# ESP32-S2-ULP register map
Vendor: ESPRESSIF SYSTEMS (SHANGHAI) CO., LTD.; Series: RISC-V ULP; File version: 1
32-bit RISC-V MCU
CPU: RV32IMC r0p0, little endian, no MPU, no FPU, 4 interrupt priority bits
Address unit: 32 bits
Registers are 32-bit, read-write, reset 0x0 unless marked. A register's access mark holds for its fields unless they carry their own. Offsets are from the block's base; lines under a group give offsets from that group; [hi:lo] are bit positions; {n}, {i} and the like mark numbered series; 'fields as' and 'values as' point back to an identical list; <NAME> marks a mode.

## Memory map
0x00008000 RTC_CNTL size 0x138 — Real-Time Clock Control
0x0000A400 RTC_IO size 0xF0 — Low-power Input/Output
0x0000C800 SENS size 0x110 — SENS Peripheral
0x0000EC00 RTC_I2C size 0x7C — Low-power I2C (Inter-Integrated Circuit) Controller

## Interrupts
0 TOUCH_DONE_INT (SENS)
1 TOUCH_INACTIVE_INT (SENS)
2 TOUCH_ACTIVE_INT (SENS)
3 SARADC1_DONE_INT (SENS)
4 SARADC2_DONE_INT (SENS)
5 TSENS_DONE_INT (SENS)
6 RISCV_START_INT (RTC_CNTL)
7 SW_INT (RTC_CNTL)
8 SWD_INT (RTC_CNTL)

## RTC_CNTL — Real-Time Clock Control
Base 0x00008000
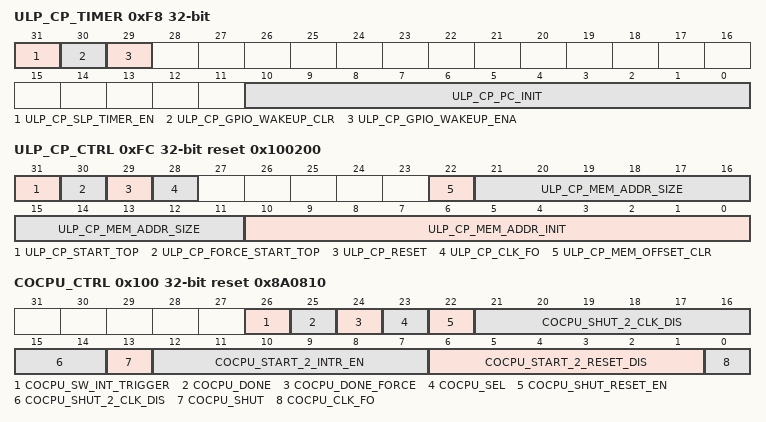
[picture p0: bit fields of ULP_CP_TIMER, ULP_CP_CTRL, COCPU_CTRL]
0xF8 ULP_CP_TIMER access per field — Configure coprocessor timer
  [31] ULP_CP_SLP_TIMER_EN rw — ULP coprocessor timer enable bit. 0: Disable hardware Timer. 1: Enable hardware timer
  [30] ULP_CP_GPIO_WAKEUP_CLR wo — Disable the option of ULP coprocessor woken up by RTC GPIO
  [29] ULP_CP_GPIO_WAKEUP_ENA rw — Enable the option of ULP coprocessor woken up by RTC GPIO
  [10:0] ULP_CP_PC_INIT rw — ULP coprocessor PC initial address
0xFC ULP_CP_CTRL access per field reset 0x100200 — ULP-FSM configuration register
  [31] ULP_CP_START_TOP rw — Write 1 to start ULP-FSM
  [30] ULP_CP_FORCE_START_TOP rw — Write 1 to start ULP-FSM by software
  [29] ULP_CP_RESET rw — ULP-FSM clock software reset
  [28] ULP_CP_CLK_FO rw — ULP-FSM clock force on
  [22] ULP_CP_MEM_OFFSET_CLR wo
  [21:11] ULP_CP_MEM_ADDR_SIZE rw
  [10:0] ULP_CP_MEM_ADDR_INIT rw
0x100 COCPU_CTRL access per field reset 0x8A0810 — ULP-RISCV configuration register
  [26] COCPU_SW_INT_TRIGGER wo — Trigger ULP-RISCV register interrupt
  [25] COCPU_DONE rw — DONE signal. Write 1 to this bit, ULP-RISCV will go to HALT and the timer starts counting
  [24] COCPU_DONE_FORCE rw — 0: select ULP-FSM DONE signal. 1: select ULP-RISCV DONE signal
  [23] COCPU_SEL rw — 0: select ULP-RISCV. 1: select ULP-FSM
  [22] COCPU_SHUT_RESET_EN rw — This bit is used to reset ULP-RISCV
  [21:14] COCPU_SHUT_2_CLK_DIS rw — Time from shut down ULP-RISCV to disable clock
  [13] COCPU_SHUT rw — Shut down ULP-RISCV
  [12:7] COCPU_START_2_INTR_EN rw — Time from ULP-RISCV startup to send out RISCV_START_INT interrupt
  [6:1] COCPU_START_2_RESET_DIS rw — Time from ULP-RISCV startup to pull down reset
  [0] COCPU_CLK_FO rw — ULP-RISCV clock force on
0x130 ULP_CP_TIMER_1 reset 0xC800 — Configure sleep cycle of the timer
  [31:8] ULP_CP_TIMER_SLP_CYCLE — Set sleep cycles for ULP coprocessor timer

## SENS — SENS Peripheral
Base 0x0000C800
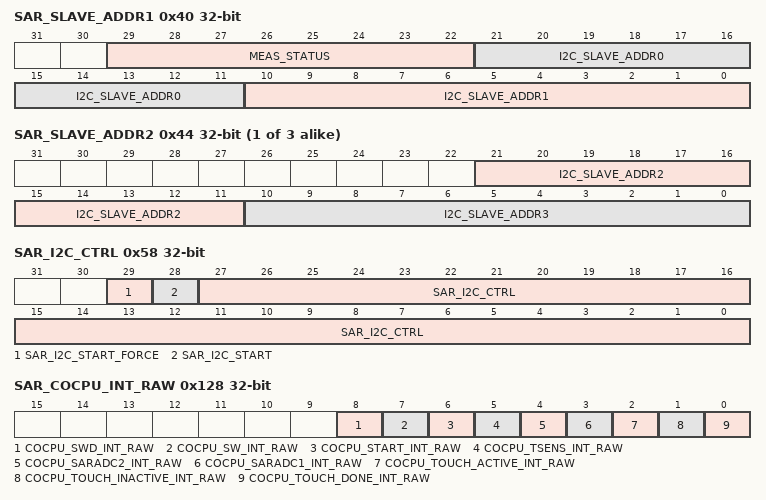
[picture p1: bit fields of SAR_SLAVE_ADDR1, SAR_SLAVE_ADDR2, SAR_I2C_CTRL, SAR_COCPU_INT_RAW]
0x40 SAR_SLAVE_ADDR1 access per field — Configure slave addresses 0-1 of RTC I2C
  [29:22] MEAS_STATUS ro
  [21:11] I2C_SLAVE_ADDR0 rw — RTC I2C slave address 0
  [10:0] I2C_SLAVE_ADDR1 rw — RTC I2C slave address 1
{0x3C+4i} SAR_SLAVE_ADDR{i} (i=2..4) — Configure slave addresses {2i-2}-{2i-1} of RTC I2C
  [21:11] I2C_SLAVE_ADDR{2i-2} — RTC I2C slave address {2i-2}
  [10:0] I2C_SLAVE_ADDR{2i-1} — RTC I2C slave address {2i-1}
0x58 SAR_I2C_CTRL — Configure RTC I2C transmission
  [29] SAR_I2C_START_FORCE — 0: RTC I2C started by FSM. 1: RTC I2C started by software.
  [28] SAR_I2C_START — Start RTC I2C. Active only when SENS_SAR_I2C_START_FORCE = 1
  [27:0] SAR_I2C_CTRL — RTC I2C control data. Active only when SENS_SAR_I2C_START_FORCE = 1.
0x128 SAR_COCPU_INT_RAW ro — Interrupt raw bit of ULP-RISCV
  [8] COCPU_SWD_INT_RAW — SWD_INT interrupt raw bit
  [7] COCPU_SW_INT_RAW — SW_INT interrupt raw bit
  [6] COCPU_START_INT_RAW — RISCV_START_INT interrupt raw bit
  [5] COCPU_TSENS_INT_RAW — TSENS_DONE_INT interrupt raw bit
  [4] COCPU_SARADC2_INT_RAW — SARADC2_DONE_INT interrupt raw bit
  [3] COCPU_SARADC1_INT_RAW — SARADC1_DONE_INT interrupt raw bit
  [2] COCPU_TOUCH_ACTIVE_INT_RAW — TOUCH_ACTIVE_INT interrupt raw bit
  [1] COCPU_TOUCH_INACTIVE_INT_RAW — TOUCH_INACTIVE_INT interrupt raw bit
  [0] COCPU_TOUCH_DONE_INT_RAW — TOUCH_DONE_INT interrupt raw bit
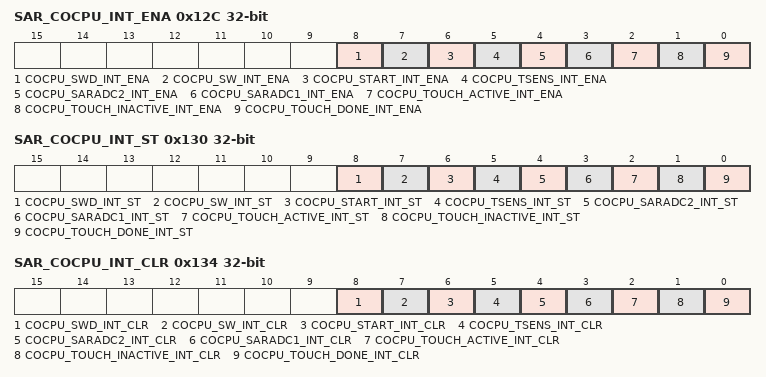
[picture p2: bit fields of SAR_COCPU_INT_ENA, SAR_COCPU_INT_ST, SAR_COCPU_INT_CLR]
0x12C SAR_COCPU_INT_ENA — Interrupt enable bit of ULP-RISCV
  [8] COCPU_SWD_INT_ENA — SWD_INT interrupt enable bit
  [7] COCPU_SW_INT_ENA — SW_INT interrupt enable bit
  [6] COCPU_START_INT_ENA — RISCV_START_INT interrupt enable bit
  [5] COCPU_TSENS_INT_ENA — TSENS_DONE_INT interrupt enable bit
  [4] COCPU_SARADC2_INT_ENA — SARADC2_DONE_INT interrupt enable bit
  [3] COCPU_SARADC1_INT_ENA — SARADC1_DONE_INT interrupt enable bit
  [2] COCPU_TOUCH_ACTIVE_INT_ENA — TOUCH_ACTIVE_INT interrupt enable bit
  [1] COCPU_TOUCH_INACTIVE_INT_ENA — TOUCH_INACTIVE_INT interrupt enable bit
  [0] COCPU_TOUCH_DONE_INT_ENA — TOUCH_DONE_INT interrupt enable bit
0x130 SAR_COCPU_INT_ST ro — Interrupt status bit of ULP-RISCV
  [8] COCPU_SWD_INT_ST — SWD_INT interrupt status bit
  [7] COCPU_SW_INT_ST — SW_INT interrupt status bit
  [6] COCPU_START_INT_ST — RISCV_START_INT interrupt status bit
  [5] COCPU_TSENS_INT_ST — TSENS_DONE_INT interrupt status bit
  [4] COCPU_SARADC2_INT_ST — SARADC2_DONE_INT interrupt status bit
  [3] COCPU_SARADC1_INT_ST — SARADC1_DONE_INT interrupt status bit
  [2] COCPU_TOUCH_ACTIVE_INT_ST — TOUCH_ACTIVE_INT interrupt status bit
  [1] COCPU_TOUCH_INACTIVE_INT_ST — TOUCH_INACTIVE_INT interrupt status bit
  [0] COCPU_TOUCH_DONE_INT_ST — TOUCH_DONE_INT interrupt status bit
0x134 SAR_COCPU_INT_CLR wo — Interrupt clear bit of ULP-RISCV
  [8] COCPU_SWD_INT_CLR — SWD_INT interrupt clear bit
  [7] COCPU_SW_INT_CLR — SW_INT interrupt clear bit
  [6] COCPU_START_INT_CLR — RISCV_START_INT interrupt clear bit
  [5] COCPU_TSENS_INT_CLR — TSENS_DONE_INT interrupt clear bit
  [4] COCPU_SARADC2_INT_CLR — SARADC2_DONE_INT interrupt clear bit
  [3] COCPU_SARADC1_INT_CLR — SARADC1_DONE_INT interrupt clear bit
  [2] COCPU_TOUCH_ACTIVE_INT_CLR — TOUCH_ACTIVE_INT interrupt clear bit
  [1] COCPU_TOUCH_INACTIVE_INT_CLR — TOUCH_INACTIVE_INT interrupt clear bit
  [0] COCPU_TOUCH_DONE_INT_CLR — TOUCH_DONE_INT interrupt clear bit

## Licence text in the file
Copyright 2023 Espressif Systems (Shanghai) PTE LTD Licensed under the Apache License, Version 2.0 (the "License"); you may not use this file except in compliance with the License. You may obtain a copy of the License at http://www.apache.org/licenses/LICENSE-2.0 Unless required by applicable law or agreed to in writing, software distributed under the License is distributed on an "AS IS" BASIS, WITHOUT WARRANTIES OR CONDITIONS OF ANY KIND, either express or implied. See the License for the specific language governing permissions and limitations under the License.
